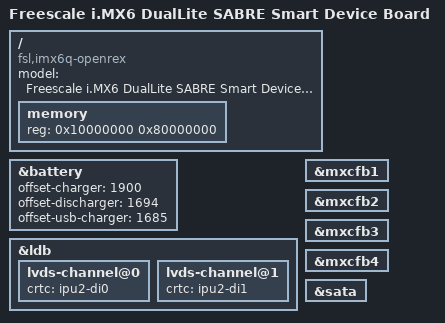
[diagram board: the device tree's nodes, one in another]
/*
 * Copyright (C) 2013 Freescale Semiconductor, Inc.
 *
 * This program is free software; you can redistribute it and/or modify
 * it under the terms of the GNU General Public License version 2 as
 * published by the Free Software Foundation.
 */

/dts-v1/;

#include "imx6q.dtsi"
#include "imx6qdl-openrex.dtsi"

/ {
	model = "Freescale i.MX6 DualLite SABRE Smart Device Board";
	compatible = "fsl,imx6q-openrex", "fsl,imx6q";
	memory {
		reg = <0x10000000 0x80000000>;
	};

};


&battery {
	offset-charger = <1900>;
	offset-discharger = <1694>;
	offset-usb-charger = <1685>;
};

&ldb {
	lvds-channel@0 {
		crtc = "ipu2-di0";
	};

	lvds-channel@1 {
		crtc = "ipu2-di1";
	};
};

&mxcfb1 {
	status = "okay";
};

&mxcfb2 {
	status = "okay";
};

&mxcfb3 {
	status = "okay";
};

&mxcfb4 {
	status = "okay";
};

&sata {
	status = "okay";
};
